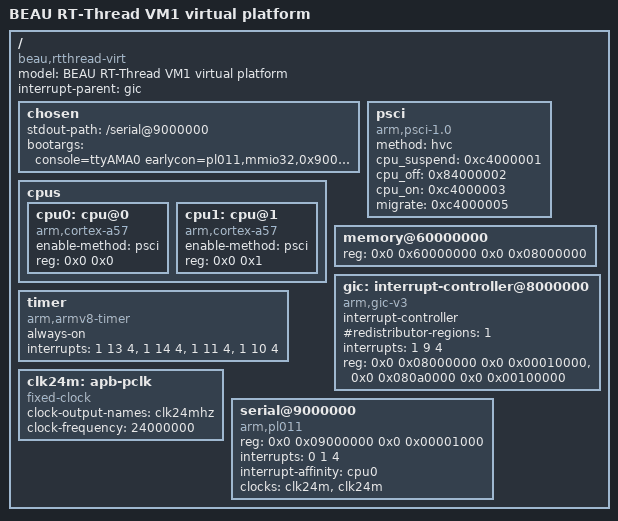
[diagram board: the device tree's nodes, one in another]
/dts-v1/;

/ {
	compatible = "beau,rtthread-virt";
	model = "BEAU RT-Thread VM1 virtual platform";
	#address-cells = <2>;
	#size-cells = <2>;
	interrupt-parent = <&gic>;

	chosen {
		stdout-path = "/serial@9000000";
		bootargs = "console=ttyAMA0 earlycon=pl011,mmio32,0x9000000 cma=8M coherent_pool=2M";
	};

	psci {
		compatible = "arm,psci-1.0", "arm,psci-0.2", "arm,psci";
		method = "hvc";
		cpu_suspend = <0xc4000001>;
		cpu_off = <0x84000002>;
		cpu_on = <0xc4000003>;
		migrate = <0xc4000005>;
	};

	cpus {
		#address-cells = <2>;
		#size-cells = <0>;

		cpu0: cpu@0 {
			device_type = "cpu";
			compatible = "arm,cortex-a57";
			enable-method = "psci";
			reg = <0x0 0x0>;
		};

		cpu1: cpu@1 {
			device_type = "cpu";
			compatible = "arm,cortex-a57";
			enable-method = "psci";
			reg = <0x0 0x1>;
		};

	};

	memory@60000000 {
		device_type = "memory";
		reg = <0x0 0x60000000 0x0 0x08000000>;
	};

	gic: interrupt-controller@8000000 {
		compatible = "arm,gic-v3";
		#interrupt-cells = <3>;
		#address-cells = <2>;
		#size-cells = <2>;
		interrupt-controller;
		#redistributor-regions = <1>;
		interrupts = <1 9 4>;
		reg = <0x0 0x08000000 0x0 0x00010000>,
		      <0x0 0x080a0000 0x0 0x00100000>;
	};

	timer {
		compatible = "arm,armv8-timer", "arm,armv7-timer";
		always-on;
		interrupts = <1 13 4>,
			     <1 14 4>,
			     <1 11 4>,
			     <1 10 4>;
	};

	clk24m: apb-pclk {
		compatible = "fixed-clock";
		clock-output-names = "clk24mhz";
		clock-frequency = <24000000>;
		#clock-cells = <0>;
	};

	serial@9000000 {
		compatible = "arm,pl011", "arm,primecell";
		reg = <0x0 0x09000000 0x0 0x00001000>;
		interrupts = <0 1 4>;
		interrupt-affinity = <&cpu0>;
		clock-names = "uartclk", "apb_pclk";
		clocks = <&clk24m &clk24m>;
		status = "okay";
	};
};
